# MCF5441x register map
Vendor: NXP; File version: 1.0
Registers are 32-bit, read-write, reset 0x0 unless marked. A register's access mark holds for its fields unless they carry their own. Offsets are from the block's base; [hi:lo] are bit positions; lines under a group give offsets from that group; {n}, {i} and the like mark numbered series.

## DTIM0
Base 0xFC070000
Same registers: DTIM1 0xFC074000, DTIM2 0xFC078000, DTIM3 0xFC07C000
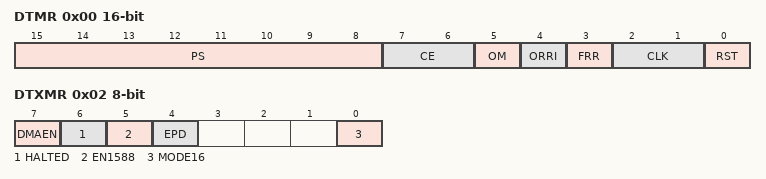
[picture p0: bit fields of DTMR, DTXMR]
0x00 DTMR 16-bit
  [15:8] PS
  [7:6] CE
  [5] OM
  [4] ORRI
  [3] FRR
  [2:1] CLK
  [0] RST
    0=RESET_TIMER_SOFTWARE_RESET; 1=ENABLE_TIMER
0x02 DTXMR 8-bit
  [7] DMAEN
    0=DISABLED; 1=ENABLED
  [6] HALTED
  [5] EN1588
  [4] EPD
    0=DISABLE; 1=ENABLE
  [0] MODE16
0x03 DTER 8-bit
  [1] REF
0x04 DTRR reset 0xFFFFFFFF
  [31:0] REF
0x08 DTCR
0x0C DTCN
  [31:0] CNT

## DSPI0
Base 0xFC05C000
Same registers: DSPI2 0xEC038000, DSPI3 0xEC03C000, DSPI1 0xFC03C000
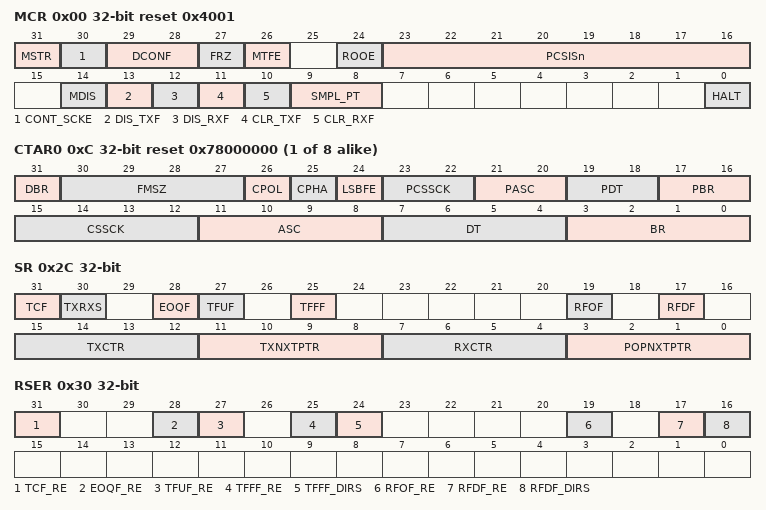
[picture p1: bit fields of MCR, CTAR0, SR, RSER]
0x00 MCR reset 0x4001
  [31] MSTR
    0=SLAVE_MODE; 1=MASTER_MODE
  [30] CONT_SCKE
    0=DISABLED; 1=ENABLED
  [29:28] DCONF
    0=SPI
  [27] FRZ
  [26] MTFE
  [24] ROOE
  [23:16] PCSISn
  [14] MDIS
  [13] DIS_TXF
    0=ENABLED; 1=DISABLED
  [12] DIS_RXF
    0=ENABLED; 1=DISABLED
  [11] CLR_TXF
  [10] CLR_RXF
  [9:8] SMPL_PT
  [0] HALT
    0=START_TRANSFERS; 1=STOP_TRANSFERS
0x08 TCR
  [31:16] SPI_TCNT
{0xC+4i} CTAR{i} reset 0x78000000 (i=0..7)
  [31] DBR, [30:27] FMSZ, [26] CPOL, [25] CPHA, [24] LSBFE, [23:22] PCSSCK, [21:20] PASC, [19:18] PDT, [17:16] PBR, [15:12] CSSCK, [11:8] ASC, [7:4] DT, [3:0] BR
0x2C SR
  [31] TCF write-1-clears
    0=NOT_COMPLETE; 1=COMPLETE
  [30] TXRXS
  [28] EOQF write-1-clears
  [27] TFUF write-1-clears
  [25] TFFF write-1-clears
    0=FULL; 1=NOT_FULL
  [19] RFOF write-1-clears
  [17] RFDF write-1-clears
    0=EMPTY; 1=NOT_EMPTY
  [15:12] TXCTR
  [11:8] TXNXTPTR
  [7:4] RXCTR
  [3:0] POPNXTPTR
0x30 RSER
  [31] TCF_RE, [28] EOQF_RE, [27] TFUF_RE, [25] TFFF_RE, [24] TFFF_DIRS, [19] RFOF_RE, [17] RFDF_RE, [16] RFDF_DIRS
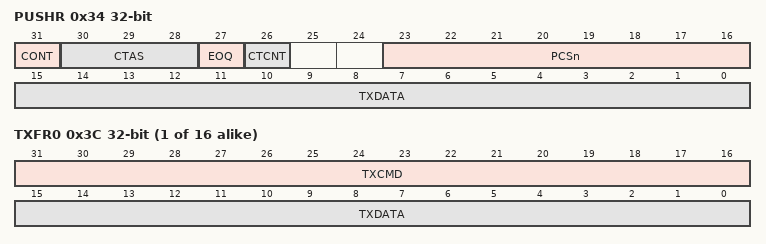
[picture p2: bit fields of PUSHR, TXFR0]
0x34 PUSHR
  [31] CONT
  [30:28] CTAS
    0=CTAR0; 1=CTAR1; 2=CTAR2; 4=CTAR4; 5=CTAR5
  [27] EOQ
  [26] CTCNT
  [23:16] PCSn
  [15:0] TXDATA
0x38 POPR ro
  [15:0] RXDATA read-modifies
{0x3C+4i} TXFR{i} ro (i=0..15)
  [31:16] TXCMD, [15:0] TXDATA
{0x7C+4i} RXFR{i} ro (i=0..15)
  [15:0] RXDATA

## EDMA
Base 0xFC044000
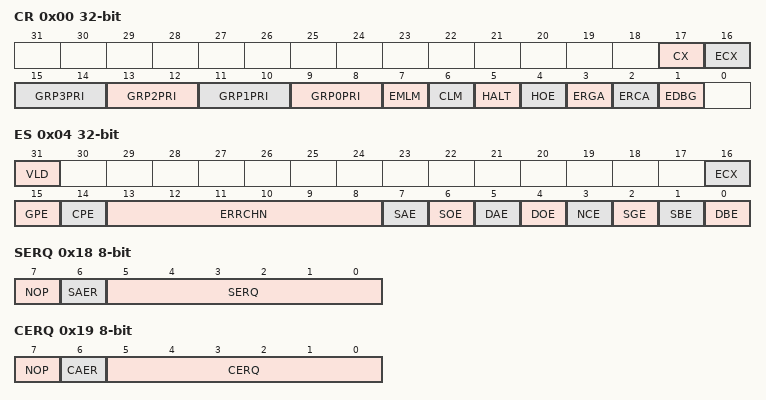
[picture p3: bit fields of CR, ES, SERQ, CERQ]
0x00 CR
  [17] CX, [16] ECX, [2n+9:2n+8] GRP{n}PRI (n=0..3), [7] EMLM, [6] CLM, [5] HALT, [4] HOE, [3] ERGA, [2] ERCA, [1] EDBG
0x04 ES ro
  [31] VLD, [16] ECX, [15] GPE, [14] CPE, [13:8] ERRCHN, [7] SAE, [6] SOE, [5] DAE, [4] DOE, [3] NCE, [2] SGE, [1] SBE, [0] DBE
0x08 ERQH
0x0C ERQL
  [31:0] ERQn
0x10 EEIH
0x14 EEIL
0x18 SERQ 8-bit wo
  [7] NOP, [6] SAER, [5:0] SERQ
0x19 CERQ 8-bit wo
  [7] NOP, [6] CAER, [5:0] CERQ
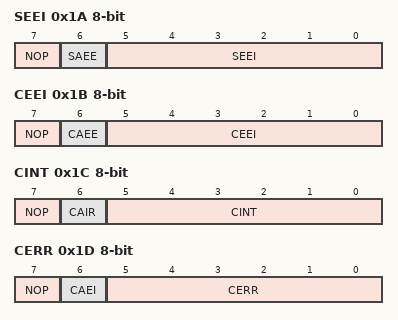
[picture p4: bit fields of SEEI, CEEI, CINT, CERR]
0x1A SEEI 8-bit wo
  [7] NOP, [6] SAEE, [5:0] SEEI
0x1B CEEI 8-bit wo
  [7] NOP, [6] CAEE, [5:0] CEEI
0x1C CINT 8-bit wo
  [7] NOP, [6] CAIR, [5:0] CINT
0x1D CERR 8-bit wo
  [7] NOP, [6] CAEI, [5:0] CERR
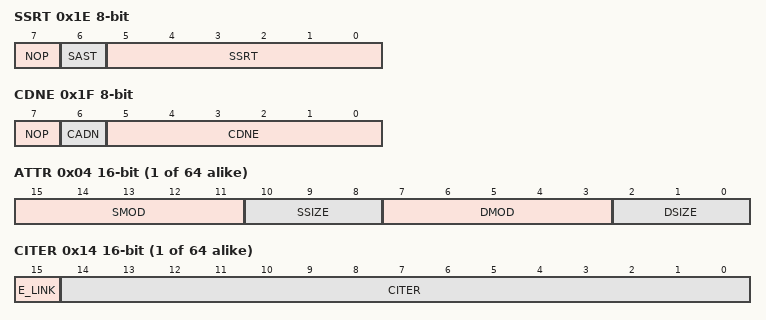
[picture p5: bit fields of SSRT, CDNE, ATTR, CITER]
0x1E SSRT 8-bit wo
  [7] NOP, [6] SAST, [5:0] SSRT
0x1F CDNE 8-bit wo
  [7] NOP, [6] CADN, [5:0] CDNE
0x20 INTH
  [31:0] INT write-1-clears
0x24 INTL
  [31:0] INT write-1-clears
0x28 ERRH
  [31:0] ERR write-1-clears
0x2C ERRL
  [31:0] ERR write-1-clears
0x30 HRSH
0x34 HRSL
  [31:0] HRS write-1-clears
{0x100+i} DCHPRI{i} (i=0..63) 8-bit reset not defined — DCHPRI{i}
{0x1000+0x20*i} TCD[{i}] (i=0..63) group — TCD[{i}]
  0x00 SADDR reset not defined
  0x04 ATTR 16-bit reset not defined
    [15:11] SMOD, [10:8] SSIZE, [7:3] DMOD, [2:0] DSIZE
  0x06 SOFF 16-bit reset not defined
  0x08 NBYTES reset not defined
  0x0C SLAST reset not defined
  0x10 DADDR reset not defined
  0x14 CITER 16-bit reset not defined
    [15] E_LINK, [14:0] CITER
  0x16 DOFF 16-bit reset not defined
  0x18 DLAST_SGA reset not defined
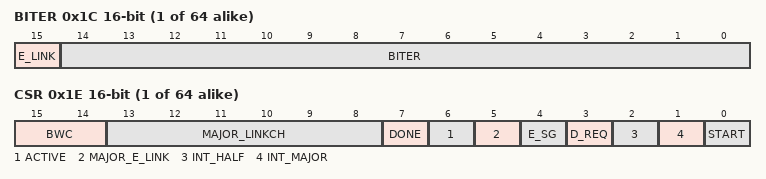
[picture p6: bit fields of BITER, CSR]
  0x1C BITER 16-bit reset not defined
    [15] E_LINK, [14:0] BITER
  0x1E CSR 16-bit reset not defined
    [15:14] BWC, [13:8] MAJOR_LINKCH, [7] DONE, [6] ACTIVE, [5] MAJOR_E_LINK, [4] E_SG, [3] D_REQ, [2] INT_HALF, [1] INT_MAJOR, [0] START

## EPORT
Base 0xFC090000
0x00 EPPAR 16-bit
0x03 EPIER 8-bit
  [7:0] EPIEn
0x06 EPFR 8-bit
  [7:0] EPFn write-1-clears
